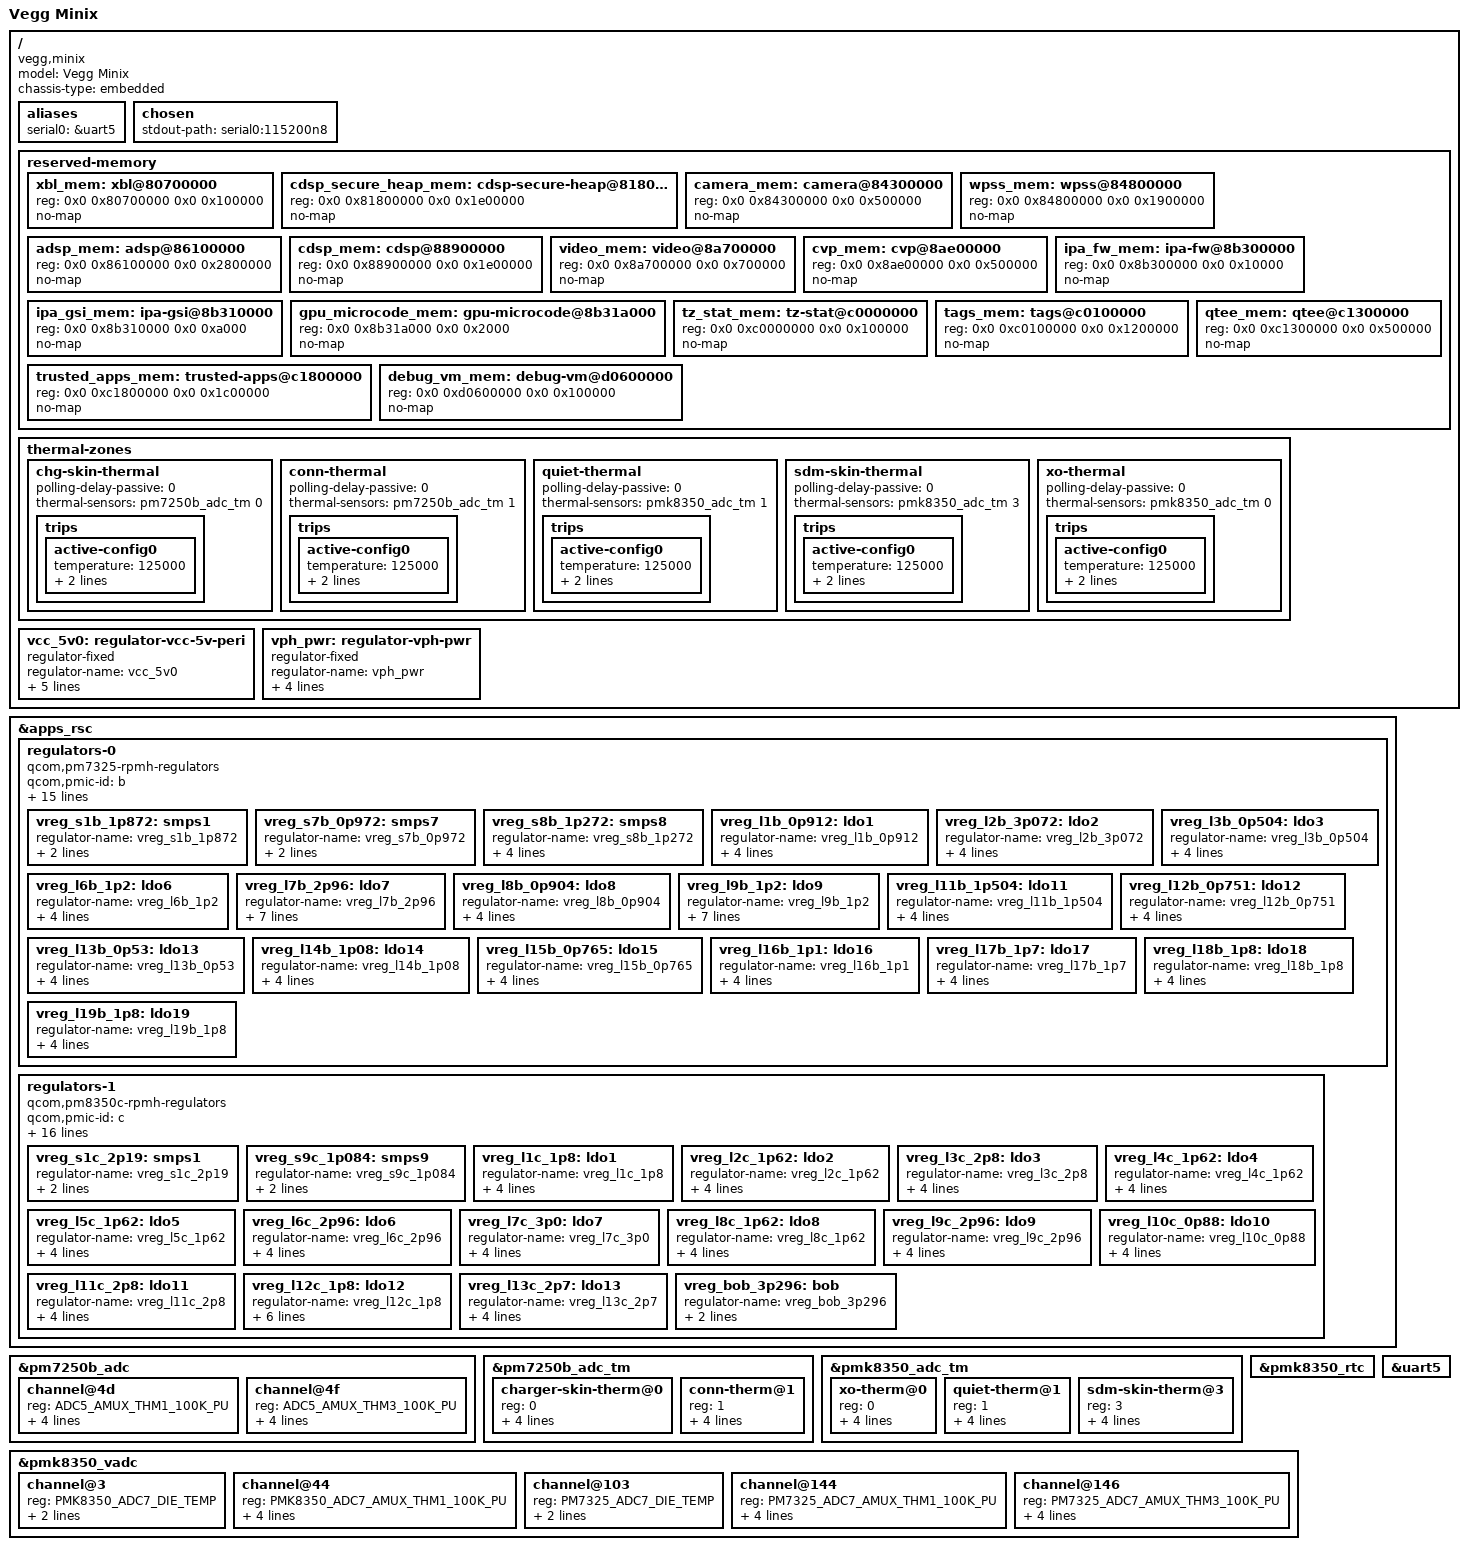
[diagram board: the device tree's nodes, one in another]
// SPDX-License-Identifier: BSD-3-Clause
/*
 * Copyright (c) 2026 Vegg Computers Pvt. Ltd.
 */

/dts-v1/;

/* PM7250B is configured to use SID8/9 */
#define PM7250B_SID 8
#define PM7250B_SID1 9

#include <dt-bindings/iio/qcom,spmi-adc7-pmk8350.h>
#include <dt-bindings/iio/qcom,spmi-adc7-pm7325.h>
#include <dt-bindings/pinctrl/qcom,pmic-gpio.h>
#include <dt-bindings/regulator/qcom,rpmh-regulator.h>

#include "kodiak.dtsi"
#include "pm7250b.dtsi"
#include "pm7325.dtsi"
#include "pm8350c.dtsi"
#include "pmk8350.dtsi"

/delete-node/ &adsp_mem;
/delete-node/ &cdsp_mem;
/delete-node/ &ipa_fw_mem;
/delete-node/ &mpss_mem;
/delete-node/ &remoteproc_mpss;
/delete-node/ &remoteproc_wpss;
/delete-node/ &rmtfs_mem;
/delete-node/ &video_mem;
/delete-node/ &wifi;
/delete-node/ &wlan_ce_mem;
/delete-node/ &wlan_fw_mem;
/delete-node/ &wpss_mem;
/delete-node/ &xbl_mem;

/ {
	model = "Vegg Minix";
	compatible = "vegg,minix", "qcom,qcm6490";
	chassis-type = "embedded";

	aliases {
		serial0 = &uart5;
	};

	chosen {
		stdout-path = "serial0:115200n8";
	};

	reserved-memory {
		xbl_mem: xbl@80700000 {
			reg = <0x0 0x80700000 0x0 0x100000>;
			no-map;
		};

		cdsp_secure_heap_mem: cdsp-secure-heap@81800000 {
			reg = <0x0 0x81800000 0x0 0x1e00000>;
			no-map;
		};

		camera_mem: camera@84300000 {
			reg = <0x0 0x84300000 0x0 0x500000>;
			no-map;
		};

		wpss_mem: wpss@84800000 {
			reg = <0x0 0x84800000 0x0 0x1900000>;
			no-map;
		};

		adsp_mem: adsp@86100000 {
			reg = <0x0 0x86100000 0x0 0x2800000>;
			no-map;
		};

		cdsp_mem: cdsp@88900000 {
			reg = <0x0 0x88900000 0x0 0x1e00000>;
			no-map;
		};

		video_mem: video@8a700000 {
			reg = <0x0 0x8a700000 0x0 0x700000>;
			no-map;
		};

		cvp_mem: cvp@8ae00000 {
			reg = <0x0 0x8ae00000 0x0 0x500000>;
			no-map;
		};

		ipa_fw_mem: ipa-fw@8b300000 {
			reg = <0x0 0x8b300000 0x0 0x10000>;
			no-map;
		};

		ipa_gsi_mem: ipa-gsi@8b310000 {
			reg = <0x0 0x8b310000 0x0 0xa000>;
			no-map;
		};

		gpu_microcode_mem: gpu-microcode@8b31a000 {
			reg = <0x0 0x8b31a000 0x0 0x2000>;
			no-map;
		};

		tz_stat_mem: tz-stat@c0000000 {
			reg = <0x0 0xc0000000 0x0 0x100000>;
			no-map;
		};

		tags_mem: tags@c0100000 {
			reg = <0x0 0xc0100000 0x0 0x1200000>;
			no-map;
		};

		qtee_mem: qtee@c1300000 {
			reg = <0x0 0xc1300000 0x0 0x500000>;
			no-map;
		};

		trusted_apps_mem: trusted-apps@c1800000 {
			reg = <0x0 0xc1800000 0x0 0x1c00000>;
			no-map;
		};

		debug_vm_mem: debug-vm@d0600000 {
			reg = <0x0 0xd0600000 0x0 0x100000>;
			no-map;
		};
	};

	thermal-zones {
		chg-skin-thermal {
			polling-delay-passive = <0>;

			thermal-sensors = <&pm7250b_adc_tm 0>;

			trips {
				active-config0 {
					temperature = <125000>;
					hysteresis = <1000>;
					type = "passive";
				};
			};
		};

		conn-thermal {
			polling-delay-passive = <0>;

			thermal-sensors = <&pm7250b_adc_tm 1>;

			trips {
				active-config0 {
					temperature = <125000>;
					hysteresis = <1000>;
					type = "passive";
				};
			};
		};

		quiet-thermal {
			polling-delay-passive = <0>;

			thermal-sensors = <&pmk8350_adc_tm 1>;

			trips {
				active-config0 {
					temperature = <125000>;
					hysteresis = <1000>;
					type = "passive";
				};
			};
		};

		sdm-skin-thermal {
			polling-delay-passive = <0>;

			thermal-sensors = <&pmk8350_adc_tm 3>;

			trips {
				active-config0 {
					temperature = <125000>;
					hysteresis = <1000>;
					type = "passive";
				};
			};
		};

		xo-thermal {
			polling-delay-passive = <0>;

			thermal-sensors = <&pmk8350_adc_tm 0>;

			trips {
				active-config0 {
					temperature = <125000>;
					hysteresis = <1000>;
					type = "passive";
				};
			};
		};
	};

	vcc_5v0: regulator-vcc-5v-peri {
		compatible = "regulator-fixed";
		regulator-name = "vcc_5v0";
		regulator-min-microvolt = <5000000>;
		regulator-max-microvolt = <5000000>;

		vin-supply = <&vph_pwr>;

		regulator-boot-on;
		regulator-always-on;
	};

	vph_pwr: regulator-vph-pwr {
		compatible = "regulator-fixed";
		regulator-name = "vph_pwr";
		regulator-min-microvolt = <3700000>;
		regulator-max-microvolt = <3700000>;

		regulator-boot-on;
		regulator-always-on;
	};
};

&apps_rsc {
	regulators-0 {
		compatible = "qcom,pm7325-rpmh-regulators";
		qcom,pmic-id = "b";

		vdd-s1-supply = <&vph_pwr>;
		vdd-s2-supply = <&vph_pwr>;
		vdd-s3-supply = <&vph_pwr>;
		vdd-s4-supply = <&vph_pwr>;
		vdd-s5-supply = <&vph_pwr>;
		vdd-s6-supply = <&vph_pwr>;
		vdd-s7-supply = <&vph_pwr>;
		vdd-s8-supply = <&vph_pwr>;
		vdd-l1-l4-l12-l15-supply = <&vreg_s7b_0p972>;
		vdd-l2-l7-supply = <&vreg_bob_3p296>;
		vdd-l6-l9-l10-supply = <&vreg_s8b_1p272>;
		vdd-l8-supply = <&vreg_s7b_0p972>;
		vdd-l11-l17-l18-l19-supply = <&vreg_s1b_1p872>;
		vdd-l13-supply = <&vreg_s7b_0p972>;
		vdd-l14-l16-supply = <&vreg_s8b_1p272>;

		vreg_s1b_1p872: smps1 {
			regulator-name = "vreg_s1b_1p872";
			regulator-min-microvolt = <1840000>;
			regulator-max-microvolt = <2040000>;
		};

		vreg_s7b_0p972: smps7 {
			regulator-name = "vreg_s7b_0p972";
			regulator-min-microvolt = <535000>;
			regulator-max-microvolt = <1120000>;
		};

		vreg_s8b_1p272: smps8 {
			regulator-name = "vreg_s8b_1p272";
			regulator-min-microvolt = <1200000>;
			regulator-max-microvolt = <1500000>;
			regulator-initial-mode = <RPMH_REGULATOR_MODE_RET>;
		};

		vreg_l1b_0p912: ldo1 {
			regulator-name = "vreg_l1b_0p912";
			regulator-min-microvolt = <825000>;
			regulator-max-microvolt = <925000>;
			regulator-initial-mode = <RPMH_REGULATOR_MODE_HPM>;
		};

		vreg_l2b_3p072: ldo2 {
			regulator-name = "vreg_l2b_3p072";
			regulator-min-microvolt = <2700000>;
			regulator-max-microvolt = <3544000>;
			regulator-initial-mode = <RPMH_REGULATOR_MODE_HPM>;
		};

		vreg_l3b_0p504: ldo3 {
			regulator-name = "vreg_l3b_0p504";
			regulator-min-microvolt = <312000>;
			regulator-max-microvolt = <650000>;
			regulator-initial-mode = <RPMH_REGULATOR_MODE_HPM>;
		};

		vreg_l6b_1p2: ldo6 {
			regulator-name = "vreg_l6b_1p2";
			regulator-min-microvolt = <1200000>;
			regulator-max-microvolt = <1260000>;
			regulator-initial-mode = <RPMH_REGULATOR_MODE_HPM>;
		};

		vreg_l7b_2p96: ldo7 {
			regulator-name = "vreg_l7b_2p96";
			regulator-min-microvolt = <2960000>;
			regulator-max-microvolt = <2960000>;
			regulator-initial-mode = <RPMH_REGULATOR_MODE_HPM>;
			regulator-allow-set-load;
			regulator-allowed-modes = <RPMH_REGULATOR_MODE_LPM
						   RPMH_REGULATOR_MODE_HPM>;
		};

		vreg_l8b_0p904: ldo8 {
			regulator-name = "vreg_l8b_0p904";
			regulator-min-microvolt = <870000>;
			regulator-max-microvolt = <970000>;
			regulator-initial-mode = <RPMH_REGULATOR_MODE_HPM>;
		};

		vreg_l9b_1p2: ldo9 {
			regulator-name = "vreg_l9b_1p2";
			regulator-min-microvolt = <1200000>;
			regulator-max-microvolt = <1200000>;
			regulator-initial-mode = <RPMH_REGULATOR_MODE_HPM>;
			regulator-allow-set-load;
			regulator-allowed-modes = <RPMH_REGULATOR_MODE_LPM
						   RPMH_REGULATOR_MODE_HPM>;
		};

		vreg_l11b_1p504: ldo11 {
			regulator-name = "vreg_l11b_1p504";
			regulator-min-microvolt = <1776000>;
			regulator-max-microvolt = <2000000>;
			regulator-initial-mode = <RPMH_REGULATOR_MODE_HPM>;
		};

		vreg_l12b_0p751: ldo12 {
			regulator-name = "vreg_l12b_0p751";
			regulator-min-microvolt = <751000>;
			regulator-max-microvolt = <824000>;
			regulator-initial-mode = <RPMH_REGULATOR_MODE_HPM>;
		};

		vreg_l13b_0p53: ldo13 {
			regulator-name = "vreg_l13b_0p53";
			regulator-min-microvolt = <530000>;
			regulator-max-microvolt = <824000>;
			regulator-initial-mode = <RPMH_REGULATOR_MODE_HPM>;
		};

		vreg_l14b_1p08: ldo14 {
			regulator-name = "vreg_l14b_1p08";
			regulator-min-microvolt = <1200000>;
			regulator-max-microvolt = <1304000>;
			regulator-initial-mode = <RPMH_REGULATOR_MODE_HPM>;
		};

		vreg_l15b_0p765: ldo15 {
			regulator-name = "vreg_l15b_0p765";
			regulator-min-microvolt = <765000>;
			regulator-max-microvolt = <1020000>;
			regulator-initial-mode = <RPMH_REGULATOR_MODE_HPM>;
		};

		vreg_l16b_1p1: ldo16 {
			regulator-name = "vreg_l16b_1p1";
			regulator-min-microvolt = <1100000>;
			regulator-max-microvolt = <1300000>;
			regulator-initial-mode = <RPMH_REGULATOR_MODE_HPM>;
		};

		vreg_l17b_1p7: ldo17 {
			regulator-name = "vreg_l17b_1p7";
			regulator-min-microvolt = <1700000>;
			regulator-max-microvolt = <1900000>;
			regulator-initial-mode = <RPMH_REGULATOR_MODE_HPM>;
		};

		vreg_l18b_1p8: ldo18 {
			regulator-name = "vreg_l18b_1p8";
			regulator-min-microvolt = <1800000>;
			regulator-max-microvolt = <2000000>;
			regulator-initial-mode = <RPMH_REGULATOR_MODE_HPM>;
		};

		vreg_l19b_1p8: ldo19 {
			regulator-name = "vreg_l19b_1p8";
			regulator-min-microvolt = <1800000>;
			regulator-max-microvolt = <2000000>;
			regulator-initial-mode = <RPMH_REGULATOR_MODE_HPM>;
		};
	};

	regulators-1 {
		compatible = "qcom,pm8350c-rpmh-regulators";
		qcom,pmic-id = "c";

		vdd-s1-supply = <&vph_pwr>;
		vdd-s2-supply = <&vph_pwr>;
		vdd-s3-supply = <&vph_pwr>;
		vdd-s4-supply = <&vph_pwr>;
		vdd-s5-supply = <&vph_pwr>;
		vdd-s6-supply = <&vph_pwr>;
		vdd-s7-supply = <&vph_pwr>;
		vdd-s8-supply = <&vph_pwr>;
		vdd-s9-supply = <&vph_pwr>;
		vdd-s10-supply = <&vph_pwr>;
		vdd-l1-l12-supply = <&vreg_s1b_1p872>;
		vdd-l2-l8-supply = <&vreg_s1b_1p872>;
		vdd-l3-l4-l5-l7-l13-supply = <&vreg_bob_3p296>;
		vdd-l6-l9-l11-supply = <&vreg_bob_3p296>;
		vdd-l10-supply = <&vreg_s7b_0p972>;
		vdd-bob-supply = <&vph_pwr>;

		vreg_s1c_2p19: smps1 {
			regulator-name = "vreg_s1c_2p19";
			regulator-min-microvolt = <2200000>;
			regulator-max-microvolt = <2208000>;
		};

		vreg_s9c_1p084: smps9 {
			regulator-name = "vreg_s9c_1p084";
			regulator-min-microvolt = <1010000>;
			regulator-max-microvolt = <1170000>;
		};

		vreg_l1c_1p8: ldo1 {
			regulator-name = "vreg_l1c_1p8";
			regulator-min-microvolt = <1800000>;
			regulator-max-microvolt = <1980000>;
			regulator-initial-mode = <RPMH_REGULATOR_MODE_HPM>;
		};

		vreg_l2c_1p62: ldo2 {
			regulator-name = "vreg_l2c_1p62";
			regulator-min-microvolt = <1620000>;
			regulator-max-microvolt = <1976000>;
			regulator-initial-mode = <RPMH_REGULATOR_MODE_HPM>;
		};

		vreg_l3c_2p8: ldo3 {
			regulator-name = "vreg_l3c_2p8";
			regulator-min-microvolt = <2800000>;
			regulator-max-microvolt = <3540000>;
			regulator-initial-mode = <RPMH_REGULATOR_MODE_HPM>;
		};

		vreg_l4c_1p62: ldo4 {
			regulator-name = "vreg_l4c_1p62";
			regulator-min-microvolt = <1620000>;
			regulator-max-microvolt = <3300000>;
			regulator-initial-mode = <RPMH_REGULATOR_MODE_HPM>;
		};

		vreg_l5c_1p62: ldo5 {
			regulator-name = "vreg_l5c_1p62";
			regulator-min-microvolt = <1620000>;
			regulator-max-microvolt = <3300000>;
			regulator-initial-mode = <RPMH_REGULATOR_MODE_HPM>;
		};

		vreg_l6c_2p96: ldo6 {
			regulator-name = "vreg_l6c_2p96";
			regulator-min-microvolt = <1650000>;
			regulator-max-microvolt = <3544000>;
			regulator-initial-mode = <RPMH_REGULATOR_MODE_HPM>;
		};

		vreg_l7c_3p0: ldo7 {
			regulator-name = "vreg_l7c_3p0";
			regulator-min-microvolt = <3000000>;
			regulator-max-microvolt = <3544000>;
			regulator-initial-mode = <RPMH_REGULATOR_MODE_HPM>;
		};

		vreg_l8c_1p62: ldo8 {
			regulator-name = "vreg_l8c_1p62";
			regulator-min-microvolt = <1800000>;
			regulator-max-microvolt = <2000000>;
			regulator-initial-mode = <RPMH_REGULATOR_MODE_HPM>;
		};

		vreg_l9c_2p96: ldo9 {
			regulator-name = "vreg_l9c_2p96";
			regulator-min-microvolt = <2700000>;
			regulator-max-microvolt = <3544000>;
			regulator-initial-mode = <RPMH_REGULATOR_MODE_HPM>;
		};

		vreg_l10c_0p88: ldo10 {
			regulator-name = "vreg_l10c_0p88";
			regulator-min-microvolt = <720000>;
			regulator-max-microvolt = <1050000>;
			regulator-initial-mode = <RPMH_REGULATOR_MODE_HPM>;
		};

		vreg_l11c_2p8: ldo11 {
			regulator-name = "vreg_l11c_2p8";
			regulator-min-microvolt = <2800000>;
			regulator-max-microvolt = <3544000>;
			regulator-initial-mode = <RPMH_REGULATOR_MODE_HPM>;
		};

		vreg_l12c_1p8: ldo12 {
			regulator-name = "vreg_l12c_1p8";
			regulator-min-microvolt = <1800000>;
			regulator-max-microvolt = <2000000>;
			regulator-initial-mode = <RPMH_REGULATOR_MODE_HPM>;

			/*
			 * VREG_L12C_1P8 supplies the Ampak WLAN/BT module
			 * VDDIO and the external 32.768 kHz oscillator.
			 */
			regulator-always-on;
			regulator-boot-on;
		};

		vreg_l13c_2p7: ldo13 {
			regulator-name = "vreg_l13c_2p7";
			regulator-min-microvolt = <2700000>;
			regulator-max-microvolt = <3544000>;
			regulator-initial-mode = <RPMH_REGULATOR_MODE_HPM>;
		};

		vreg_bob_3p296: bob {
			regulator-name = "vreg_bob_3p296";
			regulator-min-microvolt = <3008000>;
			regulator-max-microvolt = <3300000>;
		};
	};
};

&pm7250b_adc {
	channel@4d {
		reg = <ADC5_AMUX_THM1_100K_PU>;
		qcom,ratiometric;
		qcom,hw-settle-time = <200>;
		qcom,pre-scaling = <1 1>;
		label = "charger_skin_therm";
	};

	channel@4f {
		reg = <ADC5_AMUX_THM3_100K_PU>;
		qcom,ratiometric;
		qcom,hw-settle-time = <200>;
		qcom,pre-scaling = <1 1>;
		label = "conn_therm";
	};
};

&pm7250b_adc_tm {
	status = "okay";

	charger-skin-therm@0 {
		reg = <0>;
		io-channels = <&pm7250b_adc ADC5_AMUX_THM1_100K_PU>;
		qcom,ratiometric;
		qcom,hw-settle-time-us = <200>;
	};

	conn-therm@1 {
		reg = <1>;
		io-channels = <&pm7250b_adc ADC5_AMUX_THM3_100K_PU>;
		qcom,ratiometric;
		qcom,hw-settle-time-us = <200>;
	};
};

&pmk8350_adc_tm {
	status = "okay";

	xo-therm@0 {
		reg = <0>;
		io-channels = <&pmk8350_vadc PMK8350_ADC7_AMUX_THM1_100K_PU>;
		qcom,ratiometric;
		qcom,hw-settle-time-us = <200>;
	};

	quiet-therm@1 {
		reg = <1>;
		io-channels = <&pmk8350_vadc PM7325_ADC7_AMUX_THM1_100K_PU>;
		qcom,ratiometric;
		qcom,hw-settle-time-us = <200>;
	};

	sdm-skin-therm@3 {
		reg = <3>;
		io-channels = <&pmk8350_vadc PM7325_ADC7_AMUX_THM3_100K_PU>;
		qcom,ratiometric;
		qcom,hw-settle-time-us = <200>;
	};
};

&pmk8350_rtc {
	status = "okay";
};

&pmk8350_vadc {
	status = "okay";

	channel@3 {
		reg = <PMK8350_ADC7_DIE_TEMP>;
		qcom,pre-scaling = <1 1>;
		label = "pmk8350_die_therm";
	};

	channel@44 {
		reg = <PMK8350_ADC7_AMUX_THM1_100K_PU>;
		qcom,ratiometric;
		qcom,hw-settle-time = <200>;
		qcom,pre-scaling = <1 1>;
		label = "pmk8350_xo_therm";
	};

	channel@103 {
		reg = <PM7325_ADC7_DIE_TEMP>;
		qcom,pre-scaling = <1 1>;
		label = "pm7325_die_therm";
	};

	channel@144 {
		reg = <PM7325_ADC7_AMUX_THM1_100K_PU>;
		qcom,ratiometric;
		qcom,hw-settle-time = <200>;
		qcom,pre-scaling = <1 1>;
		label = "pm7325_quiet_therm";
	};

	channel@146 {
		reg = <PM7325_ADC7_AMUX_THM3_100K_PU>;
		qcom,ratiometric;
		qcom,hw-settle-time = <200>;
		qcom,pre-scaling = <1 1>;
		label = "pm7325_sdm_skin_therm";
	};
};

&uart5 {
	status = "okay";
};
